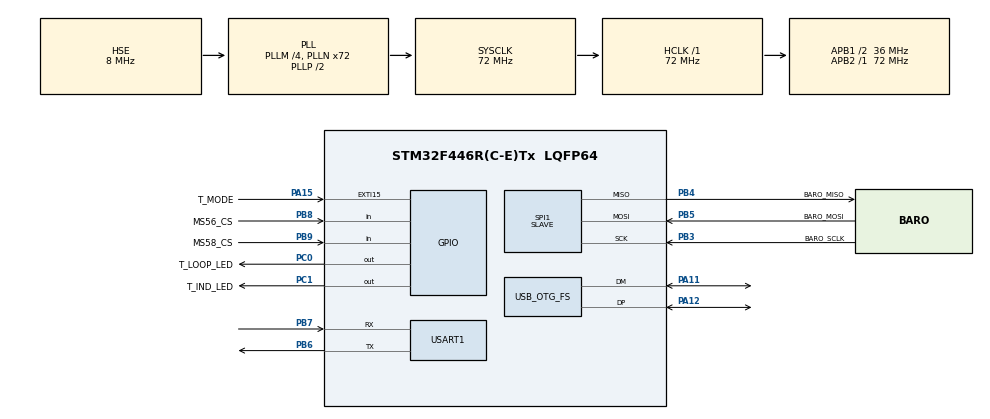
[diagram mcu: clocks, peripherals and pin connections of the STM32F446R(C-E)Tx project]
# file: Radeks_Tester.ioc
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Dma.Request0=SPI1_RX
Dma.Request1=SPI1_TX
Dma.SPI1_RX.0.Direction=DMA_PERIPH_TO_MEMORY
Dma.SPI1_RX.0.FIFOMode=DMA_FIFOMODE_DISABLE
Dma.SPI1_RX.0.Instance=DMA2_Stream0
Dma.SPI1_RX.0.MemDataAlignment=DMA_MDATAALIGN_BYTE
Dma.SPI1_RX.0.MemInc=DMA_MINC_ENABLE
Dma.SPI1_RX.0.Mode=DMA_NORMAL
Dma.SPI1_RX.0.PeriphDataAlignment=DMA_PDATAALIGN_BYTE
Dma.SPI1_RX.0.PeriphInc=DMA_PINC_DISABLE
Dma.SPI1_RX.0.Priority=DMA_PRIORITY_LOW
Dma.SPI1_TX.1.Direction=DMA_MEMORY_TO_PERIPH
Dma.SPI1_TX.1.FIFOMode=DMA_FIFOMODE_DISABLE
Dma.SPI1_TX.1.Instance=DMA2_Stream3
Dma.SPI1_TX.1.MemDataAlignment=DMA_MDATAALIGN_BYTE
Dma.SPI1_TX.1.MemInc=DMA_MINC_ENABLE
Dma.SPI1_TX.1.Mode=DMA_NORMAL
Dma.SPI1_TX.1.PeriphDataAlignment=DMA_PDATAALIGN_BYTE
Dma.SPI1_TX.1.PeriphInc=DMA_PINC_DISABLE
Dma.SPI1_TX.1.Priority=DMA_PRIORITY_LOW
Mcu.Family=STM32F4
Mcu.Name=STM32F446R(C-E)Tx
Mcu.Package=LQFP64
NVIC.DMA2_Stream0_IRQn=true\:5\:0\:true\:false\:true\:false\:true
NVIC.DMA2_Stream3_IRQn=true\:5\:0\:true\:false\:true\:false\:true
NVIC.EXTI15_10_IRQn=true\:5\:0\:true\:false\:true\:true\:true
NVIC.OTG_FS_IRQn=true\:5\:0\:true\:false\:true\:false\:true
NVIC.PriorityGroup=NVIC_PRIORITYGROUP_4
NVIC.SPI1_IRQn=true\:5\:0\:true\:false\:true\:true\:true
NVIC.TIM8_TRG_COM_TIM14_IRQn=true\:0\:0\:true\:false\:true\:true\:true
NVIC.TIM8_UP_TIM13_IRQn=true\:0\:0\:false\:false\:true\:false\:true
NVIC.TimeBase=TIM8_UP_TIM13_IRQn
NVIC.TimeBaseIP=TIM13
NVIC.USART1_IRQn=true\:5\:0\:true\:false\:true\:true\:true
PA11.Mode=Device_Only
PA11.Signal=USB_OTG_FS_DM
PA12.Mode=Device_Only
PA12.Signal=USB_OTG_FS_DP
PA15.GPIO_Label=T_MODE
PA15.Signal=GPXTI15
PB3.GPIO_Label=BARO_SCLK
PB3.Mode=Full_Duplex_Slave
PB3.Signal=SPI1_SCK
PB4.GPIO_Label=BARO_MISO
PB4.Mode=Full_Duplex_Slave
PB4.Signal=SPI1_MISO
PB5.GPIO_Label=BARO_MOSI
PB5.Mode=Full_Duplex_Slave
PB5.Signal=SPI1_MOSI
PB6.Mode=Asynchronous
PB6.Signal=USART1_TX
PB7.Mode=Asynchronous
PB7.Signal=USART1_RX
PB8.GPIO_Label=MS56_CS
PB8.Signal=GPIO_Input
PB9.GPIO_Label=MS58_CS
PB9.Signal=GPIO_Input
PC0.GPIO_Label=T_LOOP_LED
PC0.Signal=GPIO_Output
PC1.GPIO_Label=T_IND_LED
PC1.Signal=GPIO_Output
PH0-OSC_IN.Mode=HSE-External-Oscillator
PH0-OSC_IN.Signal=RCC_OSC_IN
PH1-OSC_OUT.Mode=HSE-External-Oscillator
PH1-OSC_OUT.Signal=RCC_OSC_OUT
ProjectManager.HeapSize=0x200
ProjectManager.StackSize=0x400
ProjectManager.TargetToolchain=SW4STM32
RCC.AHBFreq_Value=72000000
RCC.APB1CLKDivider=RCC_HCLK_DIV2
RCC.APB1Freq_Value=36000000
RCC.APB1TimFreq_Value=72000000
RCC.APB2Freq_Value=72000000
RCC.APB2TimFreq_Value=72000000
RCC.CortexFreq_Value=72000000
RCC.HCLKFreq_Value=72000000
RCC.HSE_VALUE=8000000
RCC.PLLM=4
RCC.PLLN=72
RCC.PLLQ=3
RCC.PLLSourceVirtual=RCC_PLLSOURCE_HSE
RCC.SYSCLKFreq_VALUE=72000000
RCC.SYSCLKSource=RCC_SYSCLKSOURCE_PLLCLK
RCC.USBFreq_Value=48000000
RCC.VCOOutputFreq_Value=144000000
SPI1.Direction=SPI_DIRECTION_2LINES
SPI1.Mode=SPI_MODE_SLAVE
SPI1.VirtualType=VM_SLAVE
USART1.VirtualMode=VM_ASYNC
USB_DEVICE.CLASS_NAME_FS=CDC
USB_DEVICE.PID_CDC_FS=22336
USB_DEVICE.USBD_MAX_STR_DESC_SIZ-CDC_FS=1024
USB_DEVICE.VirtualMode-CDC_FS=Cdc
USB_DEVICE.VirtualModeFS=Cdc_FS
USB_OTG_FS.Sof_enable=ENABLE
USB_OTG_FS.VirtualMode=Device_Only
VP_SYS_VS_tim13.Mode=TIM13
VP_TIM14_VS_ClockSourceINT.Mode=Enable_Timer
VP_USB_DEVICE_VS_USB_DEVICE_CDC_FS.Mode=CDC_FS
board=custom

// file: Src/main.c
/* USER CODE BEGIN Header */
/**
  ******************************************************************************
  * @file           : main.c
  * @brief          : Main program body
  ******************************************************************************
  * @attention
  *
  * <h2><center>&copy; Copyright (c) 2020 STMicroelectronics.
  * All rights reserved.</center></h2>
  *
  * This software component is licensed by ST under BSD 3-Clause license,
  * the "License"; You may not use this file except in compliance with the
  * License. You may obtain a copy of the License at:
  *                        opensource.org/licenses/BSD-3-Clause
  *
  ******************************************************************************
  */
/* USER CODE END Header */

#include "main.h"
#include "dma.h"
#include "spi.h"
#include "tim.h"
#include "usart.h"
#include "usb_device.h"
#include "gpio.h"

/* USER CODE BEGIN Includes */
#include "SS_common.h"
#include "SS_platform.h"

/* USER CODE END Includes */

/* USER CODE BEGIN PV */
uint8_t txbuff;
uint8_t rxbuff;
/* USER CODE END PV */

void SystemClock_Config(void);

int main(void)
{

  /* MCU Configuration--------------------------------------------------------*/

  /* Reset of all peripherals, Initializes the Flash interface and the Systick. */
  HAL_Init();

  /* Configure the system clock */
  SystemClock_Config();

  /* Initialize all configured peripherals */
  MX_GPIO_Init();
  MX_DMA_Init();
  MX_TIM14_Init();
  MX_USART1_UART_Init();
  MX_SPI1_Init();
  MX_USB_DEVICE_Init();
  /* USER CODE BEGIN 2 */
  SS_platform_init();
  SS_init();

  /* USER CODE END 2 */

  /* Infinite loop */
  while (1)
  {

  }
}

void SystemClock_Config(void)
{
  RCC_OscInitTypeDef RCC_OscInitStruct = {0};
  RCC_ClkInitTypeDef RCC_ClkInitStruct = {0};
  RCC_PeriphCLKInitTypeDef PeriphClkInitStruct = {0};

  /** Configure the main internal regulator output voltage
  */
  __HAL_RCC_PWR_CLK_ENABLE();
  __HAL_PWR_VOLTAGESCALING_CONFIG(PWR_REGULATOR_VOLTAGE_SCALE3);
  /** Initializes the CPU, AHB and APB busses clocks
  */
  RCC_OscInitStruct.OscillatorType = RCC_OSCILLATORTYPE_HSE;
  RCC_OscInitStruct.HSEState = RCC_HSE_ON;
  RCC_OscInitStruct.PLL.PLLState = RCC_PLL_ON;
  RCC_OscInitStruct.PLL.PLLSource = RCC_PLLSOURCE_HSE;
  RCC_OscInitStruct.PLL.PLLM = 4;
  RCC_OscInitStruct.PLL.PLLN = 72;
  RCC_OscInitStruct.PLL.PLLP = RCC_PLLP_DIV2;
  RCC_OscInitStruct.PLL.PLLQ = 3;
  RCC_OscInitStruct.PLL.PLLR = 2;
  if (HAL_RCC_OscConfig(&RCC_OscInitStruct) != HAL_OK)
  {
    Error_Handler();
  }
  /** Initializes the CPU, AHB and APB busses clocks
  */
  RCC_ClkInitStruct.ClockType = RCC_CLOCKTYPE_HCLK|RCC_CLOCKTYPE_SYSCLK
                              |RCC_CLOCKTYPE_PCLK1|RCC_CLOCKTYPE_PCLK2;
  RCC_ClkInitStruct.SYSCLKSource = RCC_SYSCLKSOURCE_PLLCLK;
  RCC_ClkInitStruct.AHBCLKDivider = RCC_SYSCLK_DIV1;
  RCC_ClkInitStruct.APB1CLKDivider = RCC_HCLK_DIV2;
  RCC_ClkInitStruct.APB2CLKDivider = RCC_HCLK_DIV1;

  if (HAL_RCC_ClockConfig(&RCC_ClkInitStruct, FLASH_LATENCY_2) != HAL_OK)
  {
    Error_Handler();
  }
  PeriphClkInitStruct.PeriphClockSelection = RCC_PERIPHCLK_CLK48;
  PeriphClkInitStruct.Clk48ClockSelection = RCC_CLK48CLKSOURCE_PLLQ;
  if (HAL_RCCEx_PeriphCLKConfig(&PeriphClkInitStruct) != HAL_OK)
  {
    Error_Handler();
  }
}

void HAL_TIM_PeriodElapsedCallback(TIM_HandleTypeDef *htim)
{
  if (htim->Instance == TIM13) {
    HAL_IncTick();
  }
}

void Error_Handler(void)
{
}

/************************ (C) COPYRIGHT STMicroelectronics *****END OF FILE****/
